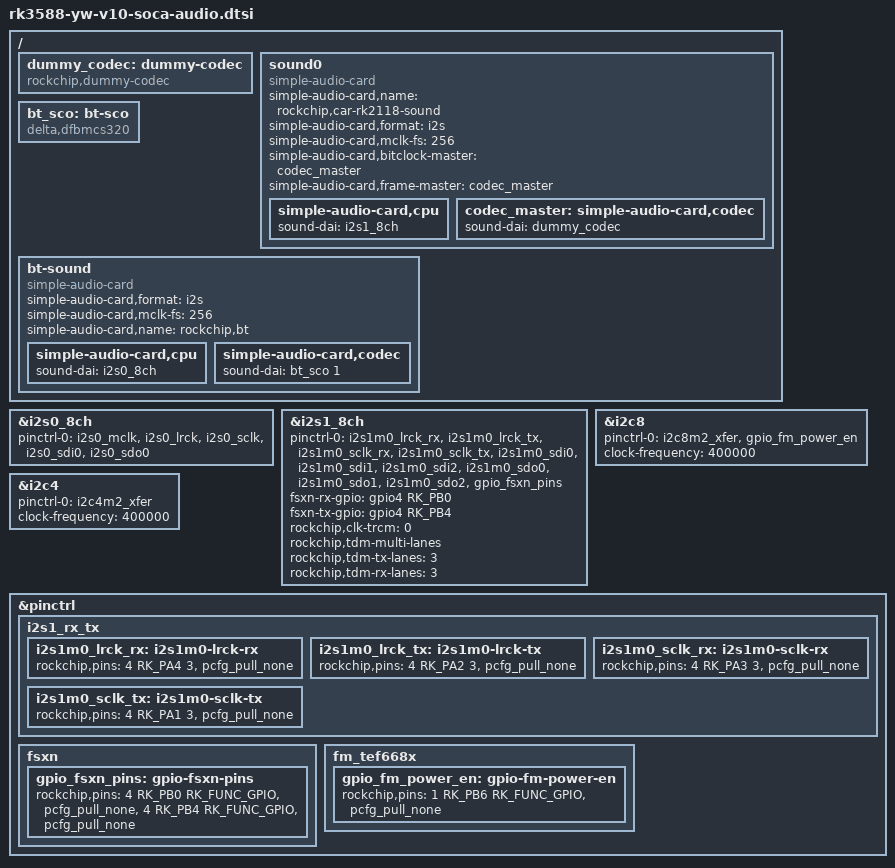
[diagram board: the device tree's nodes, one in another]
// SPDX-License-Identifier: (GPL-2.0+ OR MIT)
/*
 * Copyright (c) 2024 Rockchip Electronics Co., Ltd.
 *
 */
/ {
	dummy_codec: dummy-codec {
		compatible = "rockchip,dummy-codec";
		#sound-dai-cells = <0>;
		pinctrl-names = "default";
		status = "okay";
	};

	sound0 {
		compatible = "simple-audio-card";
		simple-audio-card,name = "rockchip,car-rk2118-sound";
		simple-audio-card,format = "i2s";
		simple-audio-card,mclk-fs = <256>;
		simple-audio-card,bitclock-master = <&codec_master>;
		simple-audio-card,frame-master = <&codec_master>;
		status = "okay";

		simple-audio-card,cpu {
			sound-dai = <&i2s1_8ch>;
		};
		codec_master: simple-audio-card,codec {
			sound-dai = <&dummy_codec>;
		};
	};

    bt_sco: bt-sco {
        compatible = "delta,dfbmcs320";
        #sound-dai-cells = <1>;
        status = "okay";
    };

    bt-sound {
        compatible = "simple-audio-card";
        simple-audio-card,format = "i2s";
        simple-audio-card,mclk-fs = <256>;
        simple-audio-card,name = "rockchip,bt";
        simple-audio-card,cpu {
            sound-dai = <&i2s0_8ch>;
        };
        simple-audio-card,codec {
            sound-dai = <&bt_sco 1>;
        };
    };
};

&i2s0_8ch {
	status = "okay";
	pinctrl-0 = <&i2s0_mclk
             &i2s0_lrck
		     &i2s0_sclk
		     &i2s0_sdi0
		     &i2s0_sdo0>;
};

&i2s1_8ch {
	pinctrl-0 = <&i2s1m0_lrck_rx
			&i2s1m0_lrck_tx
			&i2s1m0_sclk_rx
			&i2s1m0_sclk_tx
			&i2s1m0_sdi0
			&i2s1m0_sdi1
			&i2s1m0_sdi2
			&i2s1m0_sdo0
			&i2s1m0_sdo1
			&i2s1m0_sdo2
			&gpio_fsxn_pins>;
	fsxn-rx-gpio = <&gpio4 RK_PB0 GPIO_ACTIVE_HIGH>;
	fsxn-tx-gpio = <&gpio4 RK_PB4 GPIO_ACTIVE_HIGH>;
	rockchip,clk-trcm = <0>;
	rockchip,tdm-multi-lanes;
	rockchip,tdm-tx-lanes = <3>;
	rockchip,tdm-rx-lanes = <3>;
	/delete-property/ rockchip,trcm-sync-tx-only;
	status = "okay";
};

&i2c8 {
	pinctrl-0 = <&i2c8m2_xfer &gpio_fm_power_en>;
	clock-frequency = <400000>;
	status = "okay";
    //BT
};

&i2c4 {
	pinctrl-0 = <&i2c4m2_xfer>;
	clock-frequency = <400000>;
	status = "okay";
    //FM
};


&pinctrl {
	i2s1_rx_tx {
		i2s1m0_lrck_rx: i2s1m0-lrck-rx {
			rockchip,pins =
			/* i2s1m0_lrck_rx */
			<4 RK_PA4 3 &pcfg_pull_none>;
		};

		i2s1m0_lrck_tx: i2s1m0-lrck-tx {
			rockchip,pins =
			/* i2s1m0_lrck_tx */
			<4 RK_PA2 3 &pcfg_pull_none>;
		};

		i2s1m0_sclk_rx: i2s1m0-sclk-rx {
			rockchip,pins =
			/* i2s1m0_sclk_rx */
			<4 RK_PA3 3 &pcfg_pull_none>;
		};

		i2s1m0_sclk_tx: i2s1m0-sclk-tx {
			rockchip,pins =
			/* i2s1m0_sclk_tx */
			<4 RK_PA1 3 &pcfg_pull_none>;
		};
	};

	fsxn {
		/omit-if-no-ref/
		gpio_fsxn_pins: gpio-fsxn-pins {
			rockchip,pins =
			<4 RK_PB0 RK_FUNC_GPIO &pcfg_pull_none>,
			<4 RK_PB4 RK_FUNC_GPIO &pcfg_pull_none>;
		};
	};

    fm_tef668x {
		gpio_fm_power_en: gpio-fm-power-en {
			rockchip,pins =
			<1 RK_PB6 RK_FUNC_GPIO &pcfg_pull_none>;
		};
	};
};
